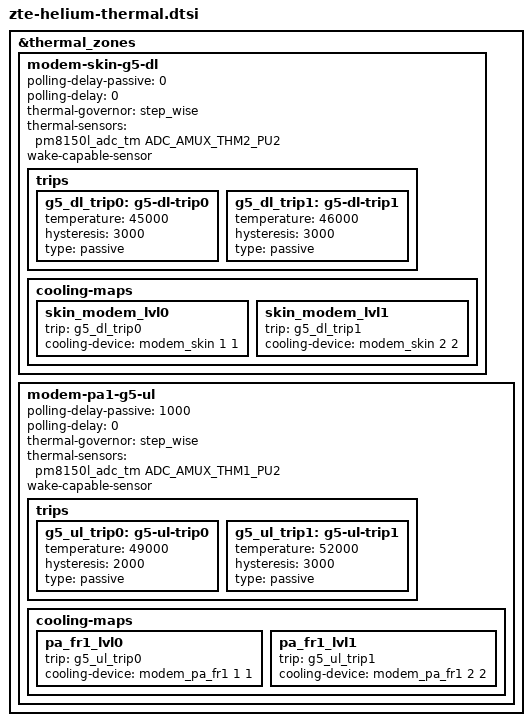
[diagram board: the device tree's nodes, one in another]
&thermal_zones {
	modem-skin-g5-dl {
		polling-delay-passive = <0>;
		polling-delay = <0>;
		thermal-governor = "step_wise";
		thermal-sensors = <&pm8150l_adc_tm ADC_AMUX_THM2_PU2>;
		wake-capable-sensor;

		trips {
			g5_dl_trip0: g5-dl-trip0 {
				temperature = <45000>;
				hysteresis = <3000>;
				type = "passive";
			};

			g5_dl_trip1: g5-dl-trip1 {
				temperature = <46000>;
				hysteresis = <3000>;
				type = "passive";
			};
		};

		cooling-maps {
			skin_modem_lvl0 {
				trip = <&g5_dl_trip0>;
				cooling-device = <&modem_skin 1 1>;
			};

			skin_modem_lvl1 {
				trip = <&g5_dl_trip1>;
				cooling-device = <&modem_skin 2 2>;
			};
		};
	};

	modem-pa1-g5-ul {
		polling-delay-passive = <1000>;
		polling-delay = <0>;
		thermal-governor = "step_wise";
		thermal-sensors = <&pm8150l_adc_tm ADC_AMUX_THM1_PU2>;
		wake-capable-sensor;

		trips {
			g5_ul_trip0: g5-ul-trip0 {
				temperature = <49000>;
				hysteresis = <2000>;
				type = "passive";
			};

			g5_ul_trip1: g5-ul-trip1 {
				temperature = <52000>;
				hysteresis = <3000>;
				type = "passive";
			};
		};

		cooling-maps {
			pa_fr1_lvl0 {
				trip = <&g5_ul_trip0>;
				cooling-device = <&modem_pa_fr1 1 1>;
			};

			pa_fr1_lvl1 {
				trip = <&g5_ul_trip1>;
				cooling-device = <&modem_pa_fr1 2 2>;
			};
		};
	};
};
